# IODELAYCONFIG register map
Vendor: Texas Instruments
Peripheral module from a debugger description file (folder am571x).
Registers are 32-bit, access per field, reset 0x0 unless marked. A register's access mark holds for its fields unless they carry their own. Offsets are as the file gives them; lines under a group give offsets from that group; [hi:lo] are bit positions; {n}, {i} and the like mark numbered series; 'fields as' and 'values as' point back to an identical list; <NAME> marks a mode.

## IODELAYCONFIG (part 1 of 2)
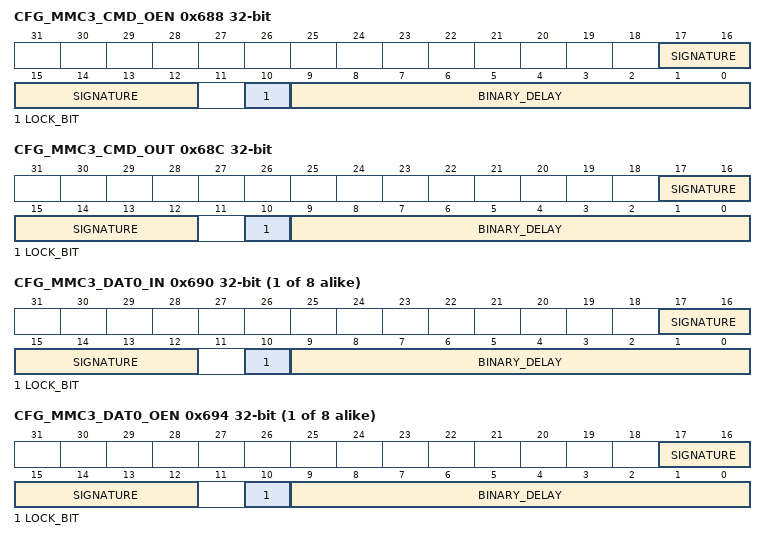
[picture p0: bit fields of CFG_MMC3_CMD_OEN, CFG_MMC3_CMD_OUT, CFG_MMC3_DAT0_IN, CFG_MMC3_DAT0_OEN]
0x688 CFG_MMC3_CMD_OEN — Delay Select Value in binary coded form for cfg_mmc3_cmd_oen interface
  [17:12] SIGNATURE rw — Write to this register will succeed only if data on these bits carries a signature of 6'h29 (6'b101001)
  [10] LOCK_BIT rw — When '1', prevents HW update to this MMR. When '0', allows HW update of this MMR.
  [9:0] BINARY_DELAY rw — Delay Select Value in binary coded form. Indicates the number of coarse (9:5) and fine (4:0) delay elements to be used on the delay line connected to this pad.
0x68C CFG_MMC3_CMD_OUT — Delay Select Value in binary coded form for cfg_mmc3_cmd_out interface
  fields as CFG_MMC3_CMD_OEN
{0x690+0xC*i} CFG_MMC3_DAT{i}_IN (i=0..7) — Delay Select Value in binary coded form for cfg_mmc3_dat{i}_in interface
  fields as CFG_MMC3_CMD_OEN
{0x694+0xC*i} CFG_MMC3_DAT{i}_OEN (i=0..7) — Delay Select Value in binary coded form for cfg_mmc3_dat{i}_oen interface
  fields as CFG_MMC3_CMD_OEN
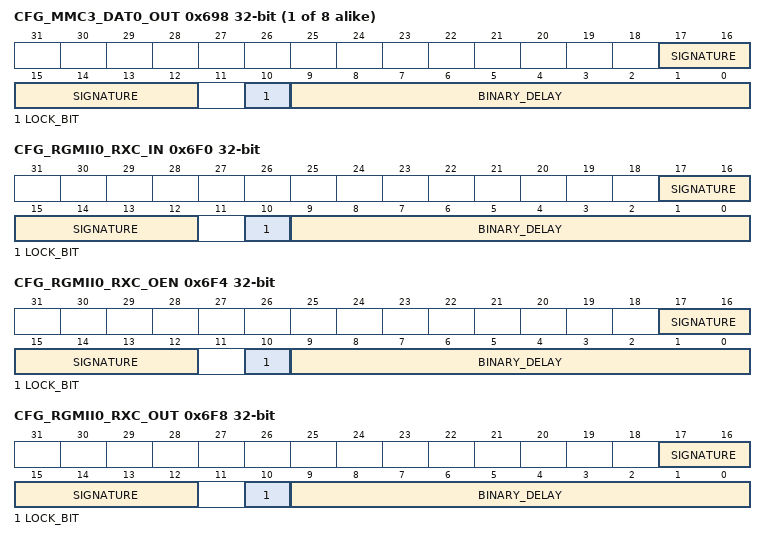
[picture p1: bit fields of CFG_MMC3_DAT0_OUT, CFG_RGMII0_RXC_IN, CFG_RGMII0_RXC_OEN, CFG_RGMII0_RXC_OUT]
{0x698+0xC*i} CFG_MMC3_DAT{i}_OUT (i=0..7) — Delay Select Value in binary coded form for cfg_mmc3_dat{i}_out interface
  fields as CFG_MMC3_CMD_OEN
0x6F0 CFG_RGMII0_RXC_IN — Delay Select Value in binary coded form for cfg_rgmii0_rxc_in interface
  fields as CFG_MMC3_CMD_OEN
0x6F4 CFG_RGMII0_RXC_OEN — Delay Select Value in binary coded form for cfg_rgmii0_rxc_oen interface
  fields as CFG_MMC3_CMD_OEN
0x6F8 CFG_RGMII0_RXC_OUT — Delay Select Value in binary coded form for cfg_rgmii0_rxc_out interface
  fields as CFG_MMC3_CMD_OEN
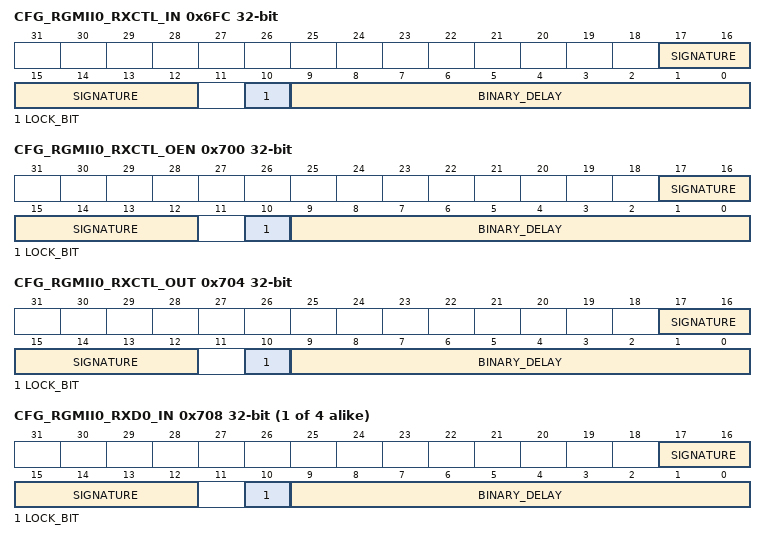
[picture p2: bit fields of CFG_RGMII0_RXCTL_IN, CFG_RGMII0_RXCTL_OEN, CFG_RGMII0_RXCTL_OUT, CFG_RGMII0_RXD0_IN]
0x6FC CFG_RGMII0_RXCTL_IN — Delay Select Value in binary coded form for cfg_rgmii0_rxctl_in interface
  fields as CFG_MMC3_CMD_OEN
0x700 CFG_RGMII0_RXCTL_OEN — Delay Select Value in binary coded form for cfg_rgmii0_rxctl_oen interface
  fields as CFG_MMC3_CMD_OEN
0x704 CFG_RGMII0_RXCTL_OUT — Delay Select Value in binary coded form for cfg_rgmii0_rxctl_out interface
  fields as CFG_MMC3_CMD_OEN
{0x708+0xC*i} CFG_RGMII0_RXD{i}_IN (i=0..3) — Delay Select Value in binary coded form for cfg_rgmii0_rxd{i}_in interface
  fields as CFG_MMC3_CMD_OEN
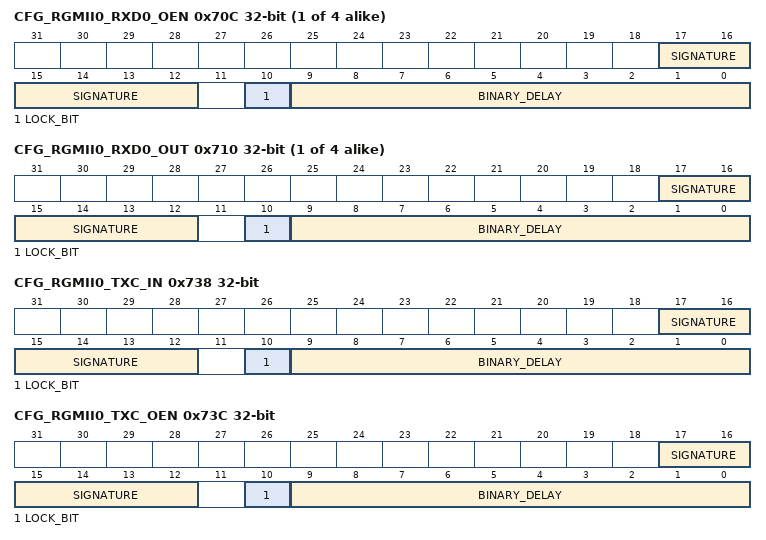
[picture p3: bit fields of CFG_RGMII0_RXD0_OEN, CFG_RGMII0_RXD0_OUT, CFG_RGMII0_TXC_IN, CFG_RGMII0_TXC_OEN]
{0x70C+0xC*i} CFG_RGMII0_RXD{i}_OEN (i=0..3) — Delay Select Value in binary coded form for cfg_rgmii0_rxd{i}_oen interface
  fields as CFG_MMC3_CMD_OEN
{0x710+0xC*i} CFG_RGMII0_RXD{i}_OUT (i=0..3) — Delay Select Value in binary coded form for cfg_rgmii0_rxd{i}_out interface
  fields as CFG_MMC3_CMD_OEN
0x738 CFG_RGMII0_TXC_IN — Delay Select Value in binary coded form for cfg_rgmii0_txc_in interface
  fields as CFG_MMC3_CMD_OEN
0x73C CFG_RGMII0_TXC_OEN — Delay Select Value in binary coded form for cfg_rgmii0_txc_oen interface
  fields as CFG_MMC3_CMD_OEN
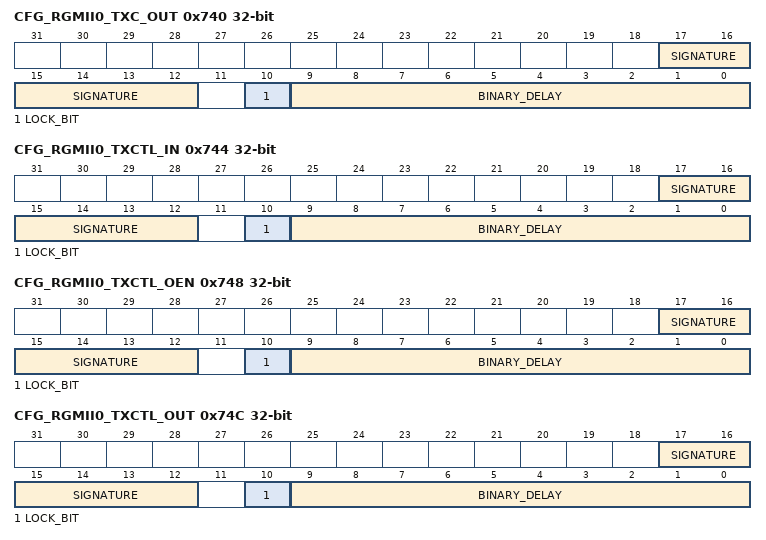
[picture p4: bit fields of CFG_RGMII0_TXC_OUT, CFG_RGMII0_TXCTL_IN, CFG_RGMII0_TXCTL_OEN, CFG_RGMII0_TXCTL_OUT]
0x740 CFG_RGMII0_TXC_OUT — Delay Select Value in binary coded form for cfg_rgmii0_txc_out interface
  fields as CFG_MMC3_CMD_OEN
0x744 CFG_RGMII0_TXCTL_IN — Delay Select Value in binary coded form for cfg_rgmii0_txctl_in interface
  fields as CFG_MMC3_CMD_OEN
0x748 CFG_RGMII0_TXCTL_OEN — Delay Select Value in binary coded form for cfg_rgmii0_txctl_oen interface
  fields as CFG_MMC3_CMD_OEN
0x74C CFG_RGMII0_TXCTL_OUT — Delay Select Value in binary coded form for cfg_rgmii0_txctl_out interface
  fields as CFG_MMC3_CMD_OEN
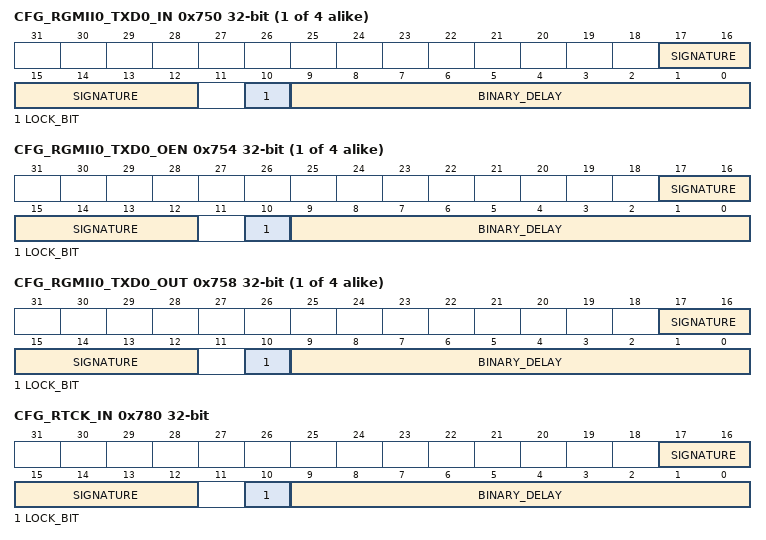
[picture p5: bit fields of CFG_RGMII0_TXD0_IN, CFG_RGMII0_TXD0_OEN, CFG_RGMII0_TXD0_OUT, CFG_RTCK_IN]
{0x750+0xC*i} CFG_RGMII0_TXD{i}_IN (i=0..3) — Delay Select Value in binary coded form for cfg_rgmii0_txd{i}_in interface
  fields as CFG_MMC3_CMD_OEN
{0x754+0xC*i} CFG_RGMII0_TXD{i}_OEN (i=0..3) — Delay Select Value in binary coded form for cfg_rgmii0_txd{i}_oen interface
  fields as CFG_MMC3_CMD_OEN
{0x758+0xC*i} CFG_RGMII0_TXD{i}_OUT (i=0..3) — Delay Select Value in binary coded form for cfg_rgmii0_txd{i}_out interface
  fields as CFG_MMC3_CMD_OEN
0x780 CFG_RTCK_IN — Delay Select Value in binary coded form for cfg_rtck_in interface
  fields as CFG_MMC3_CMD_OEN
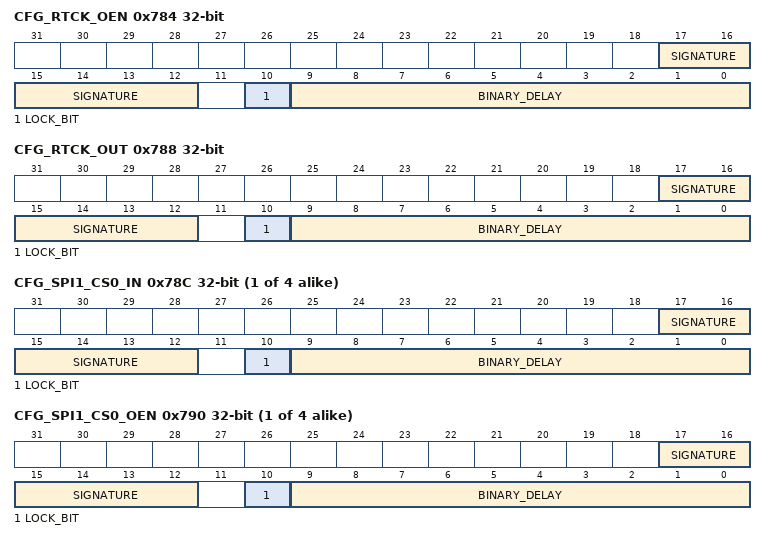
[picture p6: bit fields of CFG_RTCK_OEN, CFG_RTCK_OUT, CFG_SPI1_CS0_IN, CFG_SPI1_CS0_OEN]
0x784 CFG_RTCK_OEN — Delay Select Value in binary coded form for cfg_rtck_oen interface
  fields as CFG_MMC3_CMD_OEN
0x788 CFG_RTCK_OUT — Delay Select Value in binary coded form for cfg_rtck_out interface
  fields as CFG_MMC3_CMD_OEN
{0x78C+0xC*i} CFG_SPI1_CS{i}_IN (i=0..3) — Delay Select Value in binary coded form for cfg_spi1_cs{i}_in interface
  fields as CFG_MMC3_CMD_OEN
{0x790+0xC*i} CFG_SPI1_CS{i}_OEN (i=0..3) — Delay Select Value in binary coded form for cfg_spi1_cs{i}_oen interface
  fields as CFG_MMC3_CMD_OEN
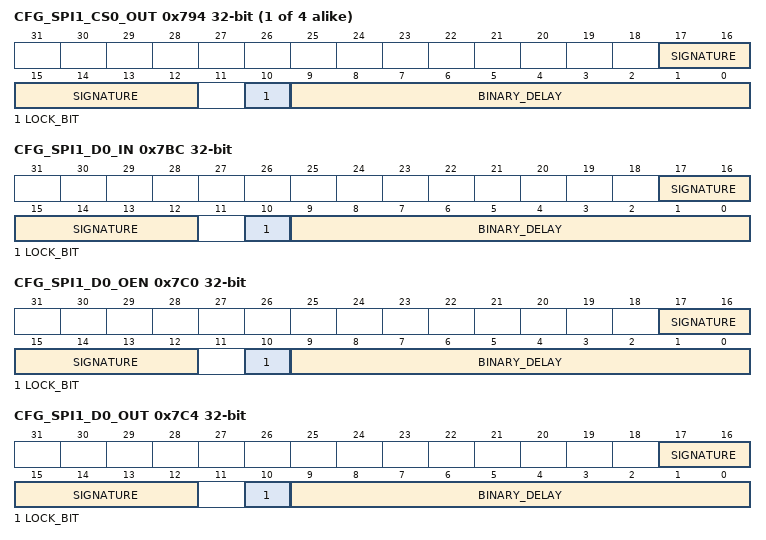
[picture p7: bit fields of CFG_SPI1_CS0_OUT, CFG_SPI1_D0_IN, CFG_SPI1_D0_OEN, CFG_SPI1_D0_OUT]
{0x794+0xC*i} CFG_SPI1_CS{i}_OUT (i=0..3) — Delay Select Value in binary coded form for cfg_spi1_cs{i}_out interface
  fields as CFG_MMC3_CMD_OEN
0x7BC CFG_SPI1_D0_IN — Delay Select Value in binary coded form for cfg_spi1_d0_in interface
  fields as CFG_MMC3_CMD_OEN
0x7C0 CFG_SPI1_D0_OEN — Delay Select Value in binary coded form for cfg_spi1_d0_oen interface
  fields as CFG_MMC3_CMD_OEN
0x7C4 CFG_SPI1_D0_OUT — Delay Select Value in binary coded form for cfg_spi1_d0_out interface
  fields as CFG_MMC3_CMD_OEN
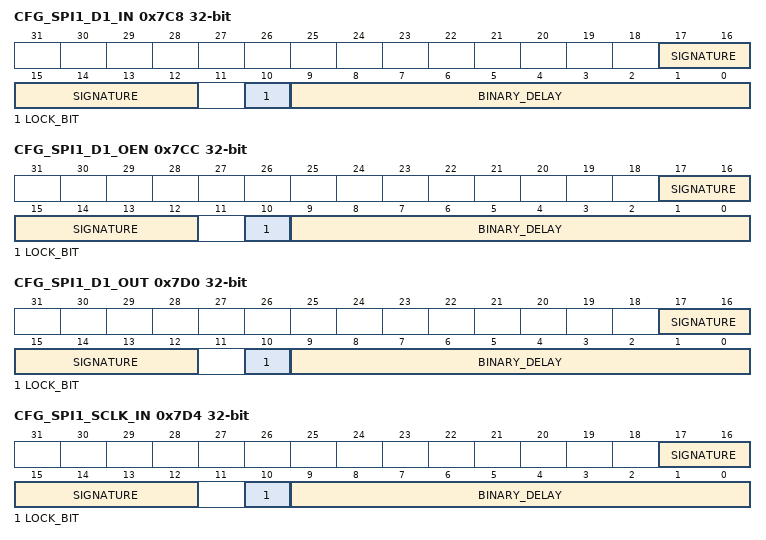
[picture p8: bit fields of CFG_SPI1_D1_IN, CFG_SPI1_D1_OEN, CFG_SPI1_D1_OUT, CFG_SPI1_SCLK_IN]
0x7C8 CFG_SPI1_D1_IN — Delay Select Value in binary coded form for cfg_spi1_d1_in interface
  fields as CFG_MMC3_CMD_OEN
0x7CC CFG_SPI1_D1_OEN — Delay Select Value in binary coded form for cfg_spi1_d1_oen interface
  fields as CFG_MMC3_CMD_OEN
0x7D0 CFG_SPI1_D1_OUT — Delay Select Value in binary coded form for cfg_spi1_d1_out interface
  fields as CFG_MMC3_CMD_OEN
0x7D4 CFG_SPI1_SCLK_IN — Delay Select Value in binary coded form for cfg_spi1_sclk_in interface
  fields as CFG_MMC3_CMD_OEN
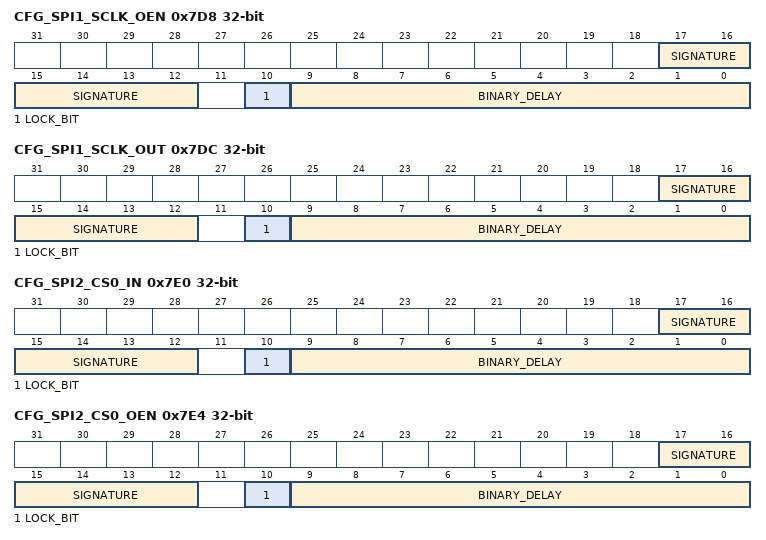
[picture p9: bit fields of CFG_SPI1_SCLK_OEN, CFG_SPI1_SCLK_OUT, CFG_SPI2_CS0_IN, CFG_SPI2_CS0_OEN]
0x7D8 CFG_SPI1_SCLK_OEN — Delay Select Value in binary coded form for cfg_spi1_sclk_oen interface
  fields as CFG_MMC3_CMD_OEN
0x7DC CFG_SPI1_SCLK_OUT — Delay Select Value in binary coded form for cfg_spi1_sclk_out interface
  fields as CFG_MMC3_CMD_OEN
0x7E0 CFG_SPI2_CS0_IN — Delay Select Value in binary coded form for cfg_spi2_cs0_in interface
  fields as CFG_MMC3_CMD_OEN
0x7E4 CFG_SPI2_CS0_OEN — Delay Select Value in binary coded form for cfg_spi2_cs0_oen interface
  fields as CFG_MMC3_CMD_OEN
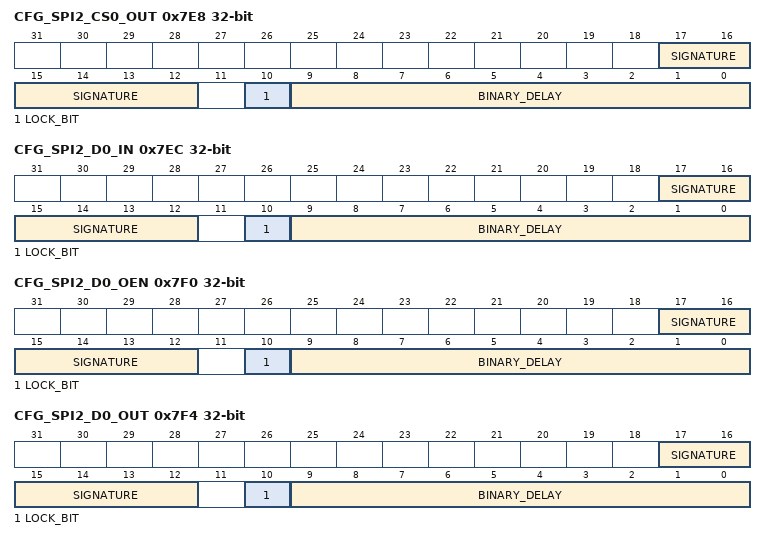
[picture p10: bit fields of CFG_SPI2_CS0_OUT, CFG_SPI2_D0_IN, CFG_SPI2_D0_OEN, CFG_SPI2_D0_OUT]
0x7E8 CFG_SPI2_CS0_OUT — Delay Select Value in binary coded form for cfg_spi2_cs0_out interface
  fields as CFG_MMC3_CMD_OEN
0x7EC CFG_SPI2_D0_IN — Delay Select Value in binary coded form for cfg_spi2_d0_in interface
  fields as CFG_MMC3_CMD_OEN
0x7F0 CFG_SPI2_D0_OEN — Delay Select Value in binary coded form for cfg_spi2_d0_oen interface
  fields as CFG_MMC3_CMD_OEN
0x7F4 CFG_SPI2_D0_OUT — Delay Select Value in binary coded form for cfg_spi2_d0_out interface
  fields as CFG_MMC3_CMD_OEN
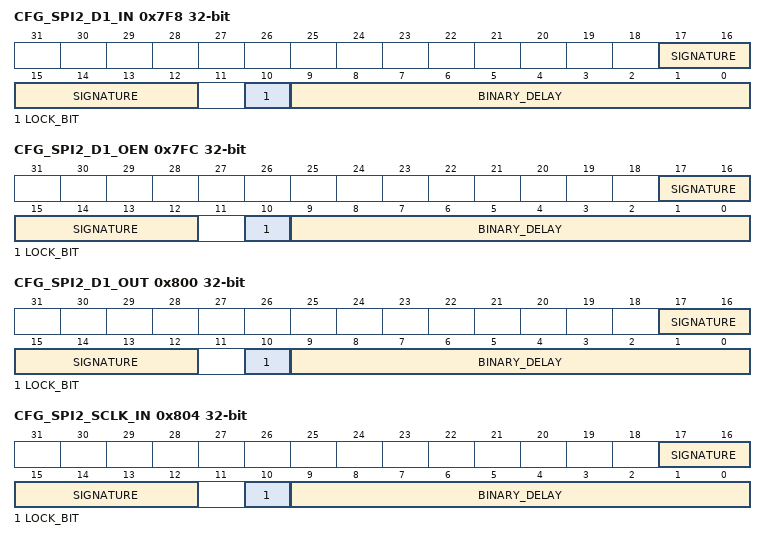
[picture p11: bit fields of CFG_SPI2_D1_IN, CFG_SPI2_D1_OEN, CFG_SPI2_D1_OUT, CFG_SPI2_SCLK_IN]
0x7F8 CFG_SPI2_D1_IN — Delay Select Value in binary coded form for cfg_spi2_d1_in interface
  fields as CFG_MMC3_CMD_OEN
0x7FC CFG_SPI2_D1_OEN — Delay Select Value in binary coded form for cfg_spi2_d1_oen interface
  fields as CFG_MMC3_CMD_OEN
0x800 CFG_SPI2_D1_OUT — Delay Select Value in binary coded form for cfg_spi2_d1_out interface
  fields as CFG_MMC3_CMD_OEN
0x804 CFG_SPI2_SCLK_IN — Delay Select Value in binary coded form for cfg_spi2_sclk_in interface
  fields as CFG_MMC3_CMD_OEN
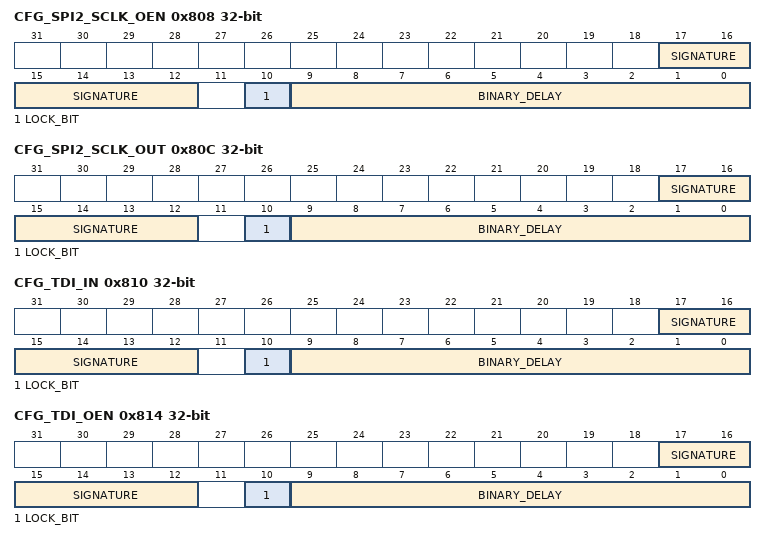
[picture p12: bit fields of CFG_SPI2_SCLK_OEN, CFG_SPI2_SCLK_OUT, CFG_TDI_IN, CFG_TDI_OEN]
0x808 CFG_SPI2_SCLK_OEN — Delay Select Value in binary coded form for cfg_spi2_sclk_oen interface
  fields as CFG_MMC3_CMD_OEN
0x80C CFG_SPI2_SCLK_OUT — Delay Select Value in binary coded form for cfg_spi2_sclk_out interface
  fields as CFG_MMC3_CMD_OEN
0x810 CFG_TDI_IN — Delay Select Value in binary coded form for cfg_tdi_in interface
  fields as CFG_MMC3_CMD_OEN
0x814 CFG_TDI_OEN — Delay Select Value in binary coded form for cfg_tdi_oen interface
  fields as CFG_MMC3_CMD_OEN
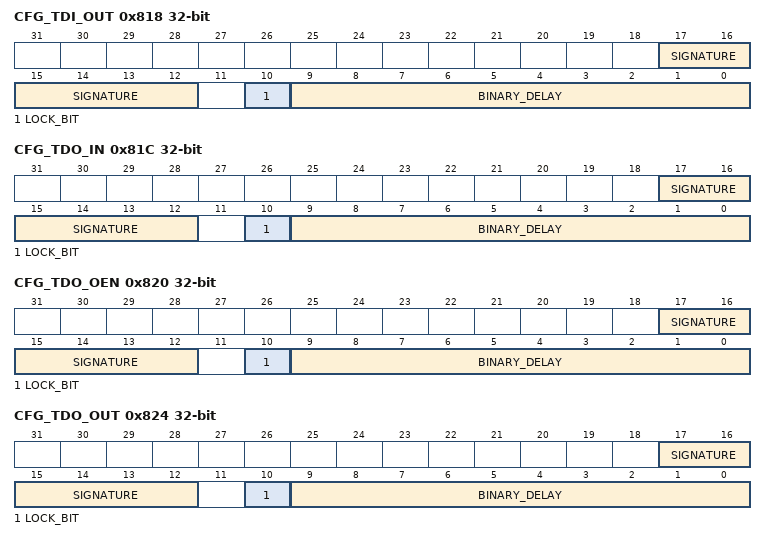
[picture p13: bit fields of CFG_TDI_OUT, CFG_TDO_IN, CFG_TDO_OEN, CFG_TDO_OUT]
0x818 CFG_TDI_OUT — Delay Select Value in binary coded form for cfg_tdi_out interface
  fields as CFG_MMC3_CMD_OEN
0x81C CFG_TDO_IN — Delay Select Value in binary coded form for cfg_tdo_in interface
  fields as CFG_MMC3_CMD_OEN
0x820 CFG_TDO_OEN — Delay Select Value in binary coded form for cfg_tdo_oen interface
  fields as CFG_MMC3_CMD_OEN
0x824 CFG_TDO_OUT — Delay Select Value in binary coded form for cfg_tdo_out interface
  fields as CFG_MMC3_CMD_OEN
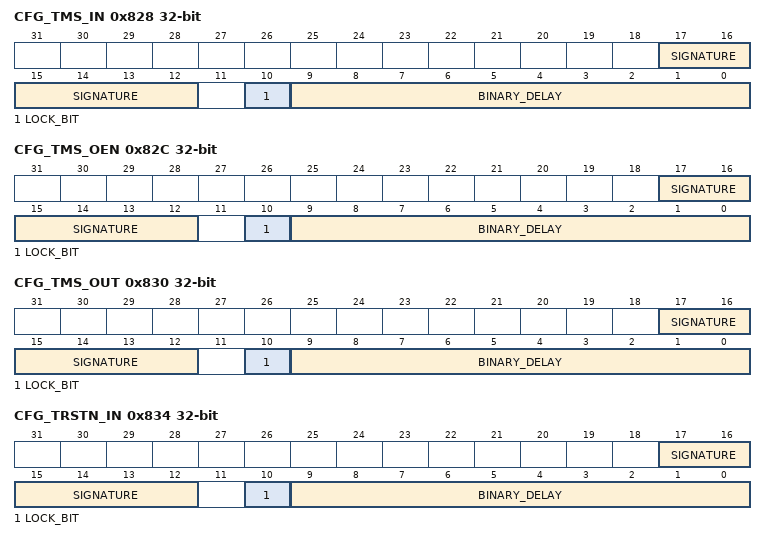
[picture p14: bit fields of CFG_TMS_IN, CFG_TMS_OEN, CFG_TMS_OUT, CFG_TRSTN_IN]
0x828 CFG_TMS_IN — Delay Select Value in binary coded form for cfg_tms_in interface
  fields as CFG_MMC3_CMD_OEN
0x82C CFG_TMS_OEN — Delay Select Value in binary coded form for cfg_tms_oen interface
  fields as CFG_MMC3_CMD_OEN
0x830 CFG_TMS_OUT — Delay Select Value in binary coded form for cfg_tms_out interface
  fields as CFG_MMC3_CMD_OEN
0x834 CFG_TRSTN_IN — Delay Select Value in binary coded form for cfg_trstn_in interface
  fields as CFG_MMC3_CMD_OEN
0x838 CFG_TRSTN_OEN — Delay Select Value in binary coded form for cfg_trstn_oen interface
  fields as CFG_MMC3_CMD_OEN
0x83C CFG_TRSTN_OUT — Delay Select Value in binary coded form for cfg_trstn_out interface
  fields as CFG_MMC3_CMD_OEN
0x840 CFG_UART1_CTSN_IN — Delay Select Value in binary coded form for cfg_uart1_ctsn_in interface
  fields as CFG_MMC3_CMD_OEN
0x844 CFG_UART1_CTSN_OEN — Delay Select Value in binary coded form for cfg_uart1_ctsn_oen interface
  fields as CFG_MMC3_CMD_OEN
0x848 CFG_UART1_CTSN_OUT — Delay Select Value in binary coded form for cfg_uart1_ctsn_out interface
  fields as CFG_MMC3_CMD_OEN
0x84C CFG_UART1_RTSN_IN — Delay Select Value in binary coded form for cfg_uart1_rtsn_in interface
  fields as CFG_MMC3_CMD_OEN
0x850 CFG_UART1_RTSN_OEN — Delay Select Value in binary coded form for cfg_uart1_rtsn_oen interface
  fields as CFG_MMC3_CMD_OEN
0x854 CFG_UART1_RTSN_OUT — Delay Select Value in binary coded form for cfg_uart1_rtsn_out interface
  fields as CFG_MMC3_CMD_OEN
0x858 CFG_UART1_RXD_IN — Delay Select Value in binary coded form for cfg_uart1_rxd_in interface
  fields as CFG_MMC3_CMD_OEN
0x85C CFG_UART1_RXD_OEN — Delay Select Value in binary coded form for cfg_uart1_rxd_oen interface
  fields as CFG_MMC3_CMD_OEN
0x860 CFG_UART1_RXD_OUT — Delay Select Value in binary coded form for cfg_uart1_rxd_out interface
  fields as CFG_MMC3_CMD_OEN
0x864 CFG_UART1_TXD_IN — Delay Select Value in binary coded form for cfg_uart1_txd_in interface
  fields as CFG_MMC3_CMD_OEN
0x868 CFG_UART1_TXD_OEN — Delay Select Value in binary coded form for cfg_uart1_txd_oen interface
  fields as CFG_MMC3_CMD_OEN
0x86C CFG_UART1_TXD_OUT — Delay Select Value in binary coded form for cfg_uart1_txd_out interface
  fields as CFG_MMC3_CMD_OEN
0x870 CFG_UART2_CTSN_IN — Delay Select Value in binary coded form for cfg_uart2_ctsn_in interface
  fields as CFG_MMC3_CMD_OEN
0x874 CFG_UART2_CTSN_OEN — Delay Select Value in binary coded form for cfg_uart2_ctsn_oen interface
  fields as CFG_MMC3_CMD_OEN
0x878 CFG_UART2_CTSN_OUT — Delay Select Value in binary coded form for cfg_uart2_ctsn_out interface
  fields as CFG_MMC3_CMD_OEN
0x87C CFG_UART2_RTSN_IN — Delay Select Value in binary coded form for cfg_uart2_rtsn_in interface
  fields as CFG_MMC3_CMD_OEN
0x880 CFG_UART2_RTSN_OEN — Delay Select Value in binary coded form for cfg_uart2_rtsn_oen interface
  fields as CFG_MMC3_CMD_OEN
0x884 CFG_UART2_RTSN_OUT — Delay Select Value in binary coded form for cfg_uart2_rtsn_out interface
  fields as CFG_MMC3_CMD_OEN
0x888 CFG_UART2_RXD_IN — Delay Select Value in binary coded form for cfg_uart2_rxd_in interface
  fields as CFG_MMC3_CMD_OEN
0x88C CFG_UART2_RXD_OEN — Delay Select Value in binary coded form for cfg_uart2_rxd_oen interface
  fields as CFG_MMC3_CMD_OEN
0x890 CFG_UART2_RXD_OUT — Delay Select Value in binary coded form for cfg_uart2_rxd_out interface
  fields as CFG_MMC3_CMD_OEN
0x894 CFG_UART2_TXD_IN — Delay Select Value in binary coded form for cfg_uart2_txd_in interface
  fields as CFG_MMC3_CMD_OEN
0x898 CFG_UART2_TXD_OEN — Delay Select Value in binary coded form for cfg_uart2_txd_oen interface
  fields as CFG_MMC3_CMD_OEN
0x89C CFG_UART2_TXD_OUT — Delay Select Value in binary coded form for cfg_uart2_txd_out interface
  fields as CFG_MMC3_CMD_OEN
0x8A0 CFG_UART3_RXD_IN — Delay Select Value in binary coded form for cfg_uart3_rxd_in interface
  fields as CFG_MMC3_CMD_OEN
0x8A4 CFG_UART3_RXD_OEN — Delay Select Value in binary coded form for cfg_uart3_rxd_oen interface
  fields as CFG_MMC3_CMD_OEN
0x8A8 CFG_UART3_RXD_OUT — Delay Select Value in binary coded form for cfg_uart3_rxd_out interface
  fields as CFG_MMC3_CMD_OEN
0x8AC CFG_UART3_TXD_IN — Delay Select Value in binary coded form for cfg_uart3_txd_in interface
  fields as CFG_MMC3_CMD_OEN
0x8B0 CFG_UART3_TXD_OEN — Delay Select Value in binary coded form for cfg_uart3_txd_oen interface
  fields as CFG_MMC3_CMD_OEN
0x8B4 CFG_UART3_TXD_OUT — Delay Select Value in binary coded form for cfg_uart3_txd_out interface
  fields as CFG_MMC3_CMD_OEN
0x8B8 CFG_USB1_DRVVBUS_IN — Delay Select Value in binary coded form for cfg_usb1_drvvbus_in interface
  fields as CFG_MMC3_CMD_OEN
0x8BC CFG_USB1_DRVVBUS_OEN — Delay Select Value in binary coded form for cfg_usb1_drvvbus_oen interface
  fields as CFG_MMC3_CMD_OEN
0x8C0 CFG_USB1_DRVVBUS_OUT — Delay Select Value in binary coded form for cfg_usb1_drvvbus_out interface
  fields as CFG_MMC3_CMD_OEN
0x8C4 CFG_USB2_DRVVBUS_IN — Delay Select Value in binary coded form for cfg_usb2_drvvbus_in interface
  fields as CFG_MMC3_CMD_OEN
0x8C8 CFG_USB2_DRVVBUS_OEN — Delay Select Value in binary coded form for cfg_usb2_drvvbus_oen interface
  fields as CFG_MMC3_CMD_OEN
0x8CC CFG_USB2_DRVVBUS_OUT — Delay Select Value in binary coded form for cfg_usb2_drvvbus_out interface
  fields as CFG_MMC3_CMD_OEN
0x8D0 CFG_VIN1A_CLK0_IN — Delay Select Value in binary coded form for cfg_vin1a_clk0_in interface
  fields as CFG_MMC3_CMD_OEN
0x8D4 CFG_VIN1A_CLK0_OEN — Delay Select Value in binary coded form for cfg_vin1a_clk0_oen interface
  fields as CFG_MMC3_CMD_OEN
0x8D8 CFG_VIN1A_CLK0_OUT — Delay Select Value in binary coded form for cfg_vin1a_clk0_out interface
  fields as CFG_MMC3_CMD_OEN
0x8DC CFG_VIN1A_D0_IN — Delay Select Value in binary coded form for cfg_vin1a_d0_in interface
  fields as CFG_MMC3_CMD_OEN
0x8E0 CFG_VIN1A_D0_OEN — Delay Select Value in binary coded form for cfg_vin1a_d0_oen interface
  fields as CFG_MMC3_CMD_OEN
0x8E4 CFG_VIN1A_D0_OUT — Delay Select Value in binary coded form for cfg_vin1a_d0_out interface
  fields as CFG_MMC3_CMD_OEN
{0x870+0xC*i} CFG_VIN1A_D{i}_IN (i=10..19) — Delay Select Value in binary coded form for cfg_vin1a_d{i}_in interface
  fields as CFG_MMC3_CMD_OEN
{0x874+0xC*i} CFG_VIN1A_D{i}_OEN (i=10..19) — Delay Select Value in binary coded form for cfg_vin1a_d{i}_oen interface
  fields as CFG_MMC3_CMD_OEN
{0x878+0xC*i} CFG_VIN1A_D{i}_OUT (i=10..19) — Delay Select Value in binary coded form for cfg_vin1a_d{i}_out interface
  fields as CFG_MMC3_CMD_OEN
0x960 CFG_VIN1A_D1_IN — Delay Select Value in binary coded form for cfg_vin1a_d1_in interface
  fields as CFG_MMC3_CMD_OEN
0x964 CFG_VIN1A_D1_OEN — Delay Select Value in binary coded form for cfg_vin1a_d1_oen interface
  fields as CFG_MMC3_CMD_OEN
0x968 CFG_VIN1A_D1_OUT — Delay Select Value in binary coded form for cfg_vin1a_d1_out interface
  fields as CFG_MMC3_CMD_OEN
{0x87C+0xC*i} CFG_VIN1A_D{i}_IN (i=20..23) — Delay Select Value in binary coded form for cfg_vin1a_d{i}_in interface
  fields as CFG_MMC3_CMD_OEN
{0x880+0xC*i} CFG_VIN1A_D{i}_OEN (i=20..23) — Delay Select Value in binary coded form for cfg_vin1a_d{i}_oen interface
  fields as CFG_MMC3_CMD_OEN
{0x884+0xC*i} CFG_VIN1A_D{i}_OUT (i=20..23) — Delay Select Value in binary coded form for cfg_vin1a_d{i}_out interface
  fields as CFG_MMC3_CMD_OEN
{0x984+0xC*i} CFG_VIN1A_D{i}_IN (i=2..9) — Delay Select Value in binary coded form for cfg_vin1a_d{i}_in interface
  fields as CFG_MMC3_CMD_OEN
{0x988+0xC*i} CFG_VIN1A_D{i}_OEN (i=2..9) — Delay Select Value in binary coded form for cfg_vin1a_d{i}_oen interface
  fields as CFG_MMC3_CMD_OEN
{0x98C+0xC*i} CFG_VIN1A_D{i}_OUT (i=2..9) — Delay Select Value in binary coded form for cfg_vin1a_d{i}_out interface
  fields as CFG_MMC3_CMD_OEN
0x9FC CFG_VIN1A_DE0_IN — Delay Select Value in binary coded form for cfg_vin1a_de0_in interface
  fields as CFG_MMC3_CMD_OEN
0xA00 CFG_VIN1A_DE0_OEN — Delay Select Value in binary coded form for cfg_vin1a_de0_oen interface
  fields as CFG_MMC3_CMD_OEN
0xA04 CFG_VIN1A_DE0_OUT — Delay Select Value in binary coded form for cfg_vin1a_de0_out interface
  fields as CFG_MMC3_CMD_OEN
0xA08 CFG_VIN1A_FLD0_IN — Delay Select Value in binary coded form for cfg_vin1a_fld0_in interface
  fields as CFG_MMC3_CMD_OEN
0xA0C CFG_VIN1A_FLD0_OEN — Delay Select Value in binary coded form for cfg_vin1a_fld0_oen interface
  fields as CFG_MMC3_CMD_OEN
0xA10 CFG_VIN1A_FLD0_OUT — Delay Select Value in binary coded form for cfg_vin1a_fld0_out interface
  fields as CFG_MMC3_CMD_OEN
0xA14 CFG_VIN1A_HSYNC0_IN — Delay Select Value in binary coded form for cfg_vin1a_hsync0_in interface
  fields as CFG_MMC3_CMD_OEN
0xA18 CFG_VIN1A_HSYNC0_OEN — Delay Select Value in binary coded form for cfg_vin1a_hsync0_oen interface
  fields as CFG_MMC3_CMD_OEN
0xA1C CFG_VIN1A_HSYNC0_OUT — Delay Select Value in binary coded form for cfg_vin1a_hsync0_out interface
  fields as CFG_MMC3_CMD_OEN
0xA20 CFG_VIN1A_VSYNC0_IN — Delay Select Value in binary coded form for cfg_vin1a_vsync0_in interface
  fields as CFG_MMC3_CMD_OEN
0xA24 CFG_VIN1A_VSYNC0_OEN — Delay Select Value in binary coded form for cfg_vin1a_vsync0_oen interface
  fields as CFG_MMC3_CMD_OEN
0xA28 CFG_VIN1A_VSYNC0_OUT — Delay Select Value in binary coded form for cfg_vin1a_vsync0_out interface
  fields as CFG_MMC3_CMD_OEN
0xA2C CFG_VIN1B_CLK1_IN — Delay Select Value in binary coded form for cfg_vin1b_clk1_in interface
  fields as CFG_MMC3_CMD_OEN
0xA30 CFG_VIN1B_CLK1_OEN — Delay Select Value in binary coded form for cfg_vin1b_clk1_oen interface
  fields as CFG_MMC3_CMD_OEN
0xA34 CFG_VIN1B_CLK1_OUT — Delay Select Value in binary coded form for cfg_vin1b_clk1_out interface
  fields as CFG_MMC3_CMD_OEN
0xA38 CFG_VIN2A_CLK0_IN — Delay Select Value in binary coded form for cfg_vin2a_clk0_in interface
  fields as CFG_MMC3_CMD_OEN
0xA3C CFG_VIN2A_CLK0_OEN — Delay Select Value in binary coded form for cfg_vin2a_clk0_oen interface
  fields as CFG_MMC3_CMD_OEN
0xA40 CFG_VIN2A_CLK0_OUT — Delay Select Value in binary coded form for cfg_vin2a_clk0_out interface
  fields as CFG_MMC3_CMD_OEN
0xA44 CFG_VIN2A_D0_IN — Delay Select Value in binary coded form for cfg_vin2a_d0_in interface
  fields as CFG_MMC3_CMD_OEN
0xA48 CFG_VIN2A_D0_OEN — Delay Select Value in binary coded form for cfg_vin2a_d0_oen interface
  fields as CFG_MMC3_CMD_OEN
0xA4C CFG_VIN2A_D0_OUT — Delay Select Value in binary coded form for cfg_vin2a_d0_out interface
  fields as CFG_MMC3_CMD_OEN
{0x9D8+0xC*i} CFG_VIN2A_D{i}_IN (i=10..19) — Delay Select Value in binary coded form for cfg_vin2a_d{i}_in interface
  fields as CFG_MMC3_CMD_OEN
{0x9DC+0xC*i} CFG_VIN2A_D{i}_OEN (i=10..19) — Delay Select Value in binary coded form for cfg_vin2a_d{i}_oen interface
  fields as CFG_MMC3_CMD_OEN
{0x9E0+0xC*i} CFG_VIN2A_D{i}_OUT (i=10..19) — Delay Select Value in binary coded form for cfg_vin2a_d{i}_out interface
  fields as CFG_MMC3_CMD_OEN
0xAC8 CFG_VIN2A_D1_IN — Delay Select Value in binary coded form for cfg_vin2a_d1_in interface
  fields as CFG_MMC3_CMD_OEN
0xACC CFG_VIN2A_D1_OEN — Delay Select Value in binary coded form for cfg_vin2a_d1_oen interface
  fields as CFG_MMC3_CMD_OEN
0xAD0 CFG_VIN2A_D1_OUT — Delay Select Value in binary coded form for cfg_vin2a_d1_out interface
  fields as CFG_MMC3_CMD_OEN
{0x9E4+0xC*i} CFG_VIN2A_D{i}_IN (i=20..23) — Delay Select Value in binary coded form for cfg_vin2a_d{i}_in interface
  fields as CFG_MMC3_CMD_OEN
{0x9E8+0xC*i} CFG_VIN2A_D{i}_OEN (i=20..23) — Delay Select Value in binary coded form for cfg_vin2a_d{i}_oen interface
  fields as CFG_MMC3_CMD_OEN
{0x9EC+0xC*i} CFG_VIN2A_D{i}_OUT (i=20..23) — Delay Select Value in binary coded form for cfg_vin2a_d{i}_out interface
  fields as CFG_MMC3_CMD_OEN
{0xAEC+0xC*i} CFG_VIN2A_D{i}_IN (i=2..9) — Delay Select Value in binary coded form for cfg_vin2a_d{i}_in interface
  fields as CFG_MMC3_CMD_OEN
{0xAF0+0xC*i} CFG_VIN2A_D{i}_OEN (i=2..9) — Delay Select Value in binary coded form for cfg_vin2a_d{i}_oen interface
  fields as CFG_MMC3_CMD_OEN
{0xAF4+0xC*i} CFG_VIN2A_D{i}_OUT (i=2..9) — Delay Select Value in binary coded form for cfg_vin2a_d{i}_out interface
  fields as CFG_MMC3_CMD_OEN
0xB64 CFG_VIN2A_DE0_IN — Delay Select Value in binary coded form for cfg_vin2a_de0_in interface
  fields as CFG_MMC3_CMD_OEN
0xB68 CFG_VIN2A_DE0_OEN — Delay Select Value in binary coded form for cfg_vin2a_de0_oen interface
  fields as CFG_MMC3_CMD_OEN
0xB6C CFG_VIN2A_DE0_OUT — Delay Select Value in binary coded form for cfg_vin2a_de0_out interface
  fields as CFG_MMC3_CMD_OEN
0xB70 CFG_VIN2A_FLD0_IN — Delay Select Value in binary coded form for cfg_vin2a_fld0_in interface
  fields as CFG_MMC3_CMD_OEN
0xB74 CFG_VIN2A_FLD0_OEN — Delay Select Value in binary coded form for cfg_vin2a_fld0_oen interface
  fields as CFG_MMC3_CMD_OEN
0xB78 CFG_VIN2A_FLD0_OUT — Delay Select Value in binary coded form for cfg_vin2a_fld0_out interface
  fields as CFG_MMC3_CMD_OEN
0xB7C CFG_VIN2A_HSYNC0_IN — Delay Select Value in binary coded form for cfg_vin2a_hsync0_in interface
  fields as CFG_MMC3_CMD_OEN
0xB80 CFG_VIN2A_HSYNC0_OEN — Delay Select Value in binary coded form for cfg_vin2a_hsync0_oen interface
  fields as CFG_MMC3_CMD_OEN
0xB84 CFG_VIN2A_HSYNC0_OUT — Delay Select Value in binary coded form for cfg_vin2a_hsync0_out interface
  fields as CFG_MMC3_CMD_OEN
0xB88 CFG_VIN2A_VSYNC0_IN — Delay Select Value in binary coded form for cfg_vin2a_vsync0_in interface
  fields as CFG_MMC3_CMD_OEN
0xB8C CFG_VIN2A_VSYNC0_OEN — Delay Select Value in binary coded form for cfg_vin2a_vsync0_oen interface
  fields as CFG_MMC3_CMD_OEN
0xB90 CFG_VIN2A_VSYNC0_OUT — Delay Select Value in binary coded form for cfg_vin2a_vsync0_out interface
  fields as CFG_MMC3_CMD_OEN
0xB94 CFG_VOUT1_CLK_IN — Delay Select Value in binary coded form for cfg_vout1_clk_in interface
  fields as CFG_MMC3_CMD_OEN
0xB98 CFG_VOUT1_CLK_OEN — Delay Select Value in binary coded form for cfg_vout1_clk_oen interface
  fields as CFG_MMC3_CMD_OEN
0xB9C CFG_VOUT1_CLK_OUT — Delay Select Value in binary coded form for cfg_vout1_clk_out interface
  fields as CFG_MMC3_CMD_OEN
0xBA0 CFG_VOUT1_D0_IN — Delay Select Value in binary coded form for cfg_vout1_d0_in interface
  fields as CFG_MMC3_CMD_OEN
0xBA4 CFG_VOUT1_D0_OEN — Delay Select Value in binary coded form for cfg_vout1_d0_oen interface
  fields as CFG_MMC3_CMD_OEN
0xBA8 CFG_VOUT1_D0_OUT — Delay Select Value in binary coded form for cfg_vout1_d0_out interface
  fields as CFG_MMC3_CMD_OEN
{0xB34+0xC*i} CFG_VOUT1_D{i}_IN (i=10..19) — Delay Select Value in binary coded form for cfg_vout1_d{i}_in interface
  fields as CFG_MMC3_CMD_OEN
{0xB38+0xC*i} CFG_VOUT1_D{i}_OEN (i=10..19) — Delay Select Value in binary coded form for cfg_vout1_d{i}_oen interface
  fields as CFG_MMC3_CMD_OEN
{0xB3C+0xC*i} CFG_VOUT1_D{i}_OUT (i=10..19) — Delay Select Value in binary coded form for cfg_vout1_d{i}_out interface
  fields as CFG_MMC3_CMD_OEN
0xC24 CFG_VOUT1_D1_IN — Delay Select Value in binary coded form for cfg_vout1_d1_in interface
  fields as CFG_MMC3_CMD_OEN
0xC28 CFG_VOUT1_D1_OEN — Delay Select Value in binary coded form for cfg_vout1_d1_oen interface
  fields as CFG_MMC3_CMD_OEN
0xC2C CFG_VOUT1_D1_OUT — Delay Select Value in binary coded form for cfg_vout1_d1_out interface
  fields as CFG_MMC3_CMD_OEN
{0xB40+0xC*i} CFG_VOUT1_D{i}_IN (i=20..23) — Delay Select Value in binary coded form for cfg_vout1_d{i}_in interface
  fields as CFG_MMC3_CMD_OEN
{0xB44+0xC*i} CFG_VOUT1_D{i}_OEN (i=20..23) — Delay Select Value in binary coded form for cfg_vout1_d{i}_oen interface
  fields as CFG_MMC3_CMD_OEN
{0xB48+0xC*i} CFG_VOUT1_D{i}_OUT (i=20..23) — Delay Select Value in binary coded form for cfg_vout1_d{i}_out interface
  fields as CFG_MMC3_CMD_OEN
{0xC48+0xC*i} CFG_VOUT1_D{i}_IN (i=2..9) — Delay Select Value in binary coded form for cfg_vout1_d{i}_in interface
  fields as CFG_MMC3_CMD_OEN
{0xC4C+0xC*i} CFG_VOUT1_D{i}_OEN (i=2..9) — Delay Select Value in binary coded form for cfg_vout1_d{i}_oen interface
  fields as CFG_MMC3_CMD_OEN
{0xC50+0xC*i} CFG_VOUT1_D{i}_OUT (i=2..9) — Delay Select Value in binary coded form for cfg_vout1_d{i}_out interface
  fields as CFG_MMC3_CMD_OEN
0xCC0 CFG_VOUT1_DE_IN — Delay Select Value in binary coded form for cfg_vout1_de_in interface
  fields as CFG_MMC3_CMD_OEN
0xCC4 CFG_VOUT1_DE_OEN — Delay Select Value in binary coded form for cfg_vout1_de_oen interface
  fields as CFG_MMC3_CMD_OEN
0xCC8 CFG_VOUT1_DE_OUT — Delay Select Value in binary coded form for cfg_vout1_de_out interface
  fields as CFG_MMC3_CMD_OEN
0xCCC CFG_VOUT1_FLD_IN — Delay Select Value in binary coded form for cfg_vout1_fld_in interface
  fields as CFG_MMC3_CMD_OEN
0xCD0 CFG_VOUT1_FLD_OEN — Delay Select Value in binary coded form for cfg_vout1_fld_oen interface
  fields as CFG_MMC3_CMD_OEN
0xCD4 CFG_VOUT1_FLD_OUT — Delay Select Value in binary coded form for cfg_vout1_fld_out interface
  fields as CFG_MMC3_CMD_OEN
0xCD8 CFG_VOUT1_HSYNC_IN — Delay Select Value in binary coded form for cfg_vout1_hsync_in interface
  fields as CFG_MMC3_CMD_OEN
0xCDC CFG_VOUT1_HSYNC_OEN — Delay Select Value in binary coded form for cfg_vout1_hsync_oen interface
  fields as CFG_MMC3_CMD_OEN
0xCE0 CFG_VOUT1_HSYNC_OUT — Delay Select Value in binary coded form for cfg_vout1_hsync_out interface
  fields as CFG_MMC3_CMD_OEN
0xCE4 CFG_VOUT1_VSYNC_IN — Delay Select Value in binary coded form for cfg_vout1_vsync_in interface
  fields as CFG_MMC3_CMD_OEN
0xCE8 CFG_VOUT1_VSYNC_OEN — Delay Select Value in binary coded form for cfg_vout1_vsync_oen interface
  fields as CFG_MMC3_CMD_OEN
0xCEC CFG_VOUT1_VSYNC_OUT — Delay Select Value in binary coded form for cfg_vout1_vsync_out interface
  fields as CFG_MMC3_CMD_OEN
{0xCF0+0xC*i} CFG_XREF_CLK{i}_IN (i=0..3) — Delay Select Value in binary coded form for cfg_xref_clk{i}_in interface
  fields as CFG_MMC3_CMD_OEN
{0xCF4+0xC*i} CFG_XREF_CLK{i}_OEN (i=0..3) — Delay Select Value in binary coded form for cfg_xref_clk{i}_oen interface
  fields as CFG_MMC3_CMD_OEN
{0xCF8+0xC*i} CFG_XREF_CLK{i}_OUT (i=0..3) — Delay Select Value in binary coded form for cfg_xref_clk{i}_out interface
  fields as CFG_MMC3_CMD_OEN
